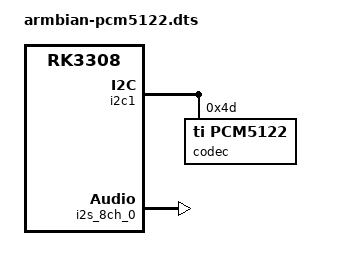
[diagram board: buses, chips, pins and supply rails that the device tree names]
/dts-v1/;
/plugin/;

/ {
        compatible = "radxa,rockpis", "rockchip,rk3308";

	fragment@0 {
		target = <&i2c1>;
		__overlay__ {
			#address-cells = <1>;
			#size-cells = <0>;
			status = "okay";

			codec: pcm5122@4d {
				#sound-dai-cells = <0>;
				compatible = "ti,pcm5122";
				reg = <0x4d>;
				status = "okay";
			};
		};
	};

        fragment@1 {
                target = <&i2s_8ch_0>;

                __overlay__ {
                        status = "okay";
                };
        };

        fragment@2 {
                target = <&i2s_8ch_2>;

                __overlay__ {
                        status = "disabled";
                };
        };

        fragment@3 {
                target-path = "/";

                __overlay__ {

		    pcm5122: pcm5122 {
                        compatible = "simple-audio-card";
                        simple-audio-card,name = "GDis_DAC";
                        simple-audio-card,format = "i2s";
                        simple-audio-card,mclk-fs = <256>;
                        status = "okay";

                        cpu_dai: simple-audio-card,cpu {
                        sound-dai = <&i2s_8ch_0>;
                        };
                                
                        codec_dai: simple-audio-card,codec {
                        sound-dai = <&codec>;
                              };
                        };
                };
        };
};
